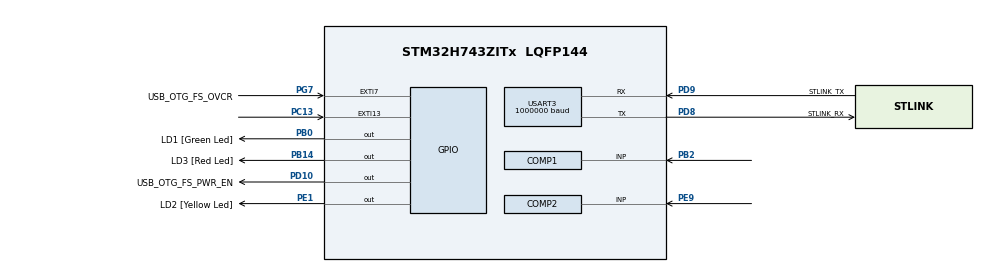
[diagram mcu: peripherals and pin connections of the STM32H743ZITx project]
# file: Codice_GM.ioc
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ADC3.Channel-0\#ChannelRegularConversion=ADC_CHANNEL_VREFINT
ADC3.ExternalTrigConv=ADC_EXTERNALTRIG_T6_TRGO
ADC3.NbrOfConversionFlag=1
ADC3.OffsetNumber-0\#ChannelRegularConversion=ADC_OFFSET_NONE
ADC3.OffsetSignedSaturation-0\#ChannelRegularConversion=DISABLE
ADC3.Rank-0\#ChannelRegularConversion=1
ADC3.SamplingTime-0\#ChannelRegularConversion=ADC_SAMPLETIME_1CYCLE_5
COMP1.Hysteresis=COMP_HYSTERESIS_MEDIUM
COMP1.TriggerMode=COMP_TRIGGERMODE_EVENT_RISING
DAC1.DAC_Channel-DAC_OUT1_Int=DAC_CHANNEL_1
Dma.ADC3.1.Direction=DMA_PERIPH_TO_MEMORY
Dma.ADC3.1.EventEnable=DISABLE
Dma.ADC3.1.FIFOMode=DMA_FIFOMODE_DISABLE
Dma.ADC3.1.Instance=DMA2_Stream0
Dma.ADC3.1.MemDataAlignment=DMA_MDATAALIGN_HALFWORD
Dma.ADC3.1.MemInc=DMA_MINC_ENABLE
Dma.ADC3.1.Mode=DMA_CIRCULAR
Dma.ADC3.1.PeriphDataAlignment=DMA_PDATAALIGN_HALFWORD
Dma.ADC3.1.PeriphInc=DMA_PINC_DISABLE
Dma.ADC3.1.Polarity=HAL_DMAMUX_REQ_GEN_RISING
Dma.ADC3.1.Priority=DMA_PRIORITY_LOW
Dma.ADC3.1.RequestNumber=1
Dma.ADC3.1.SignalID=NONE
Dma.ADC3.1.SyncEnable=DISABLE
Dma.ADC3.1.SyncPolarity=HAL_DMAMUX_SYNC_NO_EVENT
Dma.ADC3.1.SyncRequestNumber=1
Dma.ADC3.1.SyncSignalID=NONE
Dma.Request0=USART3_TX
Dma.Request1=ADC3
Dma.USART3_TX.0.Direction=DMA_MEMORY_TO_PERIPH
Dma.USART3_TX.0.EventEnable=DISABLE
Dma.USART3_TX.0.FIFOMode=DMA_FIFOMODE_DISABLE
Dma.USART3_TX.0.Instance=DMA1_Stream3
Dma.USART3_TX.0.MemDataAlignment=DMA_MDATAALIGN_BYTE
Dma.USART3_TX.0.MemInc=DMA_MINC_ENABLE
Dma.USART3_TX.0.Mode=DMA_NORMAL
Dma.USART3_TX.0.PeriphDataAlignment=DMA_PDATAALIGN_BYTE
Dma.USART3_TX.0.PeriphInc=DMA_PINC_DISABLE
Dma.USART3_TX.0.Polarity=HAL_DMAMUX_REQ_GEN_RISING
Dma.USART3_TX.0.Priority=DMA_PRIORITY_LOW
Dma.USART3_TX.0.RequestNumber=1
Dma.USART3_TX.0.SignalID=NONE
Dma.USART3_TX.0.SyncEnable=DISABLE
Dma.USART3_TX.0.SyncPolarity=HAL_DMAMUX_SYNC_NO_EVENT
Dma.USART3_TX.0.SyncRequestNumber=1
Dma.USART3_TX.0.SyncSignalID=NONE
Mcu.Family=STM32H7
Mcu.Name=STM32H743ZITx
Mcu.Package=LQFP144
NVIC.ADC3_IRQn=true\:0\:0\:false\:false\:true\:true\:true\:true
NVIC.DMA1_Stream3_IRQn=true\:0\:0\:false\:false\:true\:false\:true\:true
NVIC.DMA2_Stream0_IRQn=true\:0\:0\:false\:false\:true\:false\:true\:true
NVIC.EXTI15_10_IRQn=true\:0\:0\:false\:false\:true\:true\:true\:true
NVIC.PriorityGroup=NVIC_PRIORITYGROUP_4
NVIC.TIM6_DAC_IRQn=true\:0\:0\:false\:false\:true\:true\:true\:true
NVIC.USART3_IRQn=true\:0\:0\:false\:false\:true\:true\:true\:true
PA1.Signal=ETH_REF_CLK
PA11.Signal=USB_OTG_FS_DM
PA12.Signal=USB_OTG_FS_DP
PA2.Signal=ETH_MDIO
PA7.Signal=ETH_CRS_DV
PA8.Signal=USB_OTG_FS_SOF
PA9.Signal=USB_OTG_FS_VBUS
PB0.GPIO_Label=LD1 [Green Led]
PB0.Signal=GPIO_Output
PB13.Signal=ETH_TXD1
PB14.GPIO_Label=LD3 [Red Led]
PB14.Signal=GPIO_Output
PB2.Mode=INP
PB2.Signal=COMP1_INP
PC1.Signal=ETH_MDC
PC13.Signal=GPXTI13
PC14-OSC32_IN\ (OSC32_IN).Mode=LSE-External-Oscillator
PC14-OSC32_IN\ (OSC32_IN).Signal=RCC_OSC32_IN
PC15-OSC32_OUT\ (OSC32_OUT).Mode=LSE-External-Oscillator
PC15-OSC32_OUT\ (OSC32_OUT).Signal=RCC_OSC32_OUT
PC4.Signal=ETH_RXD0
PC5.Signal=ETH_RXD1
PD10.GPIO_Label=USB_OTG_FS_PWR_EN
PD10.Signal=GPIO_Output
PD8.GPIO_Label=STLINK_RX
PD8.Mode=Asynchronous
PD8.Signal=USART3_TX
PD9.GPIO_Label=STLINK_TX
PD9.Mode=Asynchronous
PD9.Signal=USART3_RX
PE1.GPIO_Label=LD2 [Yellow Led]
PE1.Signal=GPIO_Output
PE9.Mode=INP
PE9.Signal=COMP2_INP
PG11.Signal=ETH_TX_EN
PG13.Signal=ETH_TXD0
PG7.GPIO_Label=USB_OTG_FS_OVCR
PG7.Signal=GPXTI7
PH0-OSC_IN\ (PH0).Mode=HSE-External-Clock-Source
PH0-OSC_IN\ (PH0).Signal=RCC_OSC_IN
PH1-OSC_OUT\ (PH1).Signal=RCC_OSC_OUT
ProjectManager.HeapSize=0x200
ProjectManager.StackSize=0x400
ProjectManager.TargetToolchain=STM32CubeIDE
RCC.ADCFreq_Value=80000000
RCC.APB1Freq_Value=120000000
RCC.APB2Freq_Value=120000000
RCC.APB3Freq_Value=120000000
RCC.APB4Freq_Value=120000000
RCC.CortexFreq_Value=480000000
RCC.D1PPRE=RCC_APB3_DIV2
RCC.D2PPRE1=RCC_APB1_DIV2
RCC.D2PPRE2=RCC_APB2_DIV2
RCC.D3PPRE=RCC_APB4_DIV2
RCC.DIVM1=4
RCC.DIVM2=4
RCC.DIVN1=60
RCC.DIVN2=10
RCC.DIVQ1=4
RCC.HCLKFreq_Value=240000000
RCC.HPRE=RCC_HCLK_DIV2
RCC.HSE_VALUE=8000000
RCC.PLL2FRACN=0
RCC.PLL3FRACN=0
RCC.PLLFRACN=0
RCC.PWR_Regulator_Voltage_Scale=PWR_REGULATOR_VOLTAGE_SCALE0
RCC.SYSCLKFreq_VALUE=480000000
RCC.SYSCLKSource=RCC_SYSCLKSOURCE_PLLCLK
RCC.USBFreq_Value=240000000
TIM6.TIM_MasterOutputTrigger=TIM_TRGO_UPDATE
USART3.BaudRate=1000000
USART3.VirtualMode-Asynchronous=VM_ASYNC
VP_ADC3_TempSens_Input.Mode=IN-TempSens
VP_ADC3_Vref_Input.Mode=IN-Vrefint
VP_COMP1_VS_DACOUT1.Mode=INM_DACOUT1
VP_COMP2_VS_DACOUT1.Mode=INM_DACOUT1
VP_DAC1_VS_DACI1.Mode=DAC_OUT1_Int
VP_MEMORYMAP_VS_MEMORYMAP.Mode=CurAppReg
VP_TIM6_VS_ClockSourceINT.Mode=Enable_Timer
VP_VREFBUF_V_VREFBUF.Mode=ExternalMode
board=NUCLEO-H743ZI2

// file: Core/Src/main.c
/* USER CODE BEGIN Header */
/**
  ******************************************************************************
  * @file           : main.c
  * @brief          : Main program body
  ******************************************************************************
  * @attention
  *
  * Copyright (c) 2024 STMicroelectronics.
  * All rights reserved.
  *
  * This software is licensed under terms that can be found in the LICENSE file
  * in the root directory of this software component.
  * If no LICENSE file comes with this software, it is provided AS-IS.
  *
  ******************************************************************************
  */
/* USER CODE END Header */
#include "main.h"
#include "adc.h"
#include "comp.h"
#include "dac.h"
#include "dma.h"
#include "memorymap.h"
#include "tim.h"
#include "usart.h"
#include "gpio.h"

/* USER CODE BEGIN PTD */
#include "USART_RT.h"
#include "exponential.h"
#include "temp_volt.h"
#include "SiPM.h"
#include "LED.h"

/* USER CODE END PTD */

void SystemClock_Config(void);

int main(void)
{

  /* MCU Configuration--------------------------------------------------------*/

  /* Reset of all peripherals, Initializes the Flash interface and the Systick. */
  HAL_Init();

  /* Configure the system clock */
  SystemClock_Config();

  /* Initialize all configured peripherals */
  MX_GPIO_Init();
  MX_DMA_Init();
  MX_TIM6_Init();
  MX_USART3_UART_Init();
  MX_ADC3_Init();
  MX_DAC1_Init();
  MX_COMP1_Init();
  /* USER CODE BEGIN 2 */

  //**********************//

  //Il codice è organizzato nel sefuente modo:
  //nel main.c sono presenti tutte le esperienze commentate a seconda della necessità.
  //In questo caso l'esperienza selezionata è la catena di acqusizione dei fotoni tramite SiPM.
  //in alternativa si commenti tale sezione e si scommenti quelle interessate.

  //**********************//

// SiPM
  SiPM_comp_iniz();
  SiPM_timer_iniz();
  SiPM_DMA_iniz();
  SiPM_ADC_iniz();
  SiPM_USART_iniz();

//	USART_RT
//	RT_USART_iniz();

//	esponenziali
//	exp_USART_iniz();

//  temp_volt
//  temp_volt_ADC_iniz();
//  temp_volt_USART_iniz();

//	LED
//	LED_iniz();

  /* USER CODE END 2 */

  /* Infinite loop */
  while (1){

  }
}

void SystemClock_Config(void)
{
  RCC_OscInitTypeDef RCC_OscInitStruct = {0};
  RCC_ClkInitTypeDef RCC_ClkInitStruct = {0};

  /** Supply configuration update enable
  */
  HAL_PWREx_ConfigSupply(PWR_LDO_SUPPLY);

  /** Configure the main internal regulator output voltage
  */
  __HAL_PWR_VOLTAGESCALING_CONFIG(PWR_REGULATOR_VOLTAGE_SCALE1);

  while(!__HAL_PWR_GET_FLAG(PWR_FLAG_VOSRDY)) {}

  __HAL_RCC_SYSCFG_CLK_ENABLE();
  __HAL_PWR_VOLTAGESCALING_CONFIG(PWR_REGULATOR_VOLTAGE_SCALE0);

  while(!__HAL_PWR_GET_FLAG(PWR_FLAG_VOSRDY)) {}

  /** Initializes the RCC Oscillators according to the specified parameters
  * in the RCC_OscInitTypeDef structure.
  */
  RCC_OscInitStruct.OscillatorType = RCC_OSCILLATORTYPE_HSI;
  RCC_OscInitStruct.HSIState = RCC_HSI_DIV1;
  RCC_OscInitStruct.HSICalibrationValue = RCC_HSICALIBRATION_DEFAULT;
  RCC_OscInitStruct.PLL.PLLState = RCC_PLL_ON;
  RCC_OscInitStruct.PLL.PLLSource = RCC_PLLSOURCE_HSI;
  RCC_OscInitStruct.PLL.PLLM = 4;
  RCC_OscInitStruct.PLL.PLLN = 60;
  RCC_OscInitStruct.PLL.PLLP = 2;
  RCC_OscInitStruct.PLL.PLLQ = 4;
  RCC_OscInitStruct.PLL.PLLR = 2;
  RCC_OscInitStruct.PLL.PLLRGE = RCC_PLL1VCIRANGE_3;
  RCC_OscInitStruct.PLL.PLLVCOSEL = RCC_PLL1VCOWIDE;
  RCC_OscInitStruct.PLL.PLLFRACN = 0;
  if (HAL_RCC_OscConfig(&RCC_OscInitStruct) != HAL_OK)
  {
    Error_Handler();
  }

  /** Initializes the CPU, AHB and APB buses clocks
  */
  RCC_ClkInitStruct.ClockType = RCC_CLOCKTYPE_HCLK|RCC_CLOCKTYPE_SYSCLK
                              |RCC_CLOCKTYPE_PCLK1|RCC_CLOCKTYPE_PCLK2
                              |RCC_CLOCKTYPE_D3PCLK1|RCC_CLOCKTYPE_D1PCLK1;
  RCC_ClkInitStruct.SYSCLKSource = RCC_SYSCLKSOURCE_PLLCLK;
  RCC_ClkInitStruct.SYSCLKDivider = RCC_SYSCLK_DIV1;
  RCC_ClkInitStruct.AHBCLKDivider = RCC_HCLK_DIV2;
  RCC_ClkInitStruct.APB3CLKDivider = RCC_APB3_DIV2;
  RCC_ClkInitStruct.APB1CLKDivider = RCC_APB1_DIV2;
  RCC_ClkInitStruct.APB2CLKDivider = RCC_APB2_DIV2;
  RCC_ClkInitStruct.APB4CLKDivider = RCC_APB4_DIV2;

  if (HAL_RCC_ClockConfig(&RCC_ClkInitStruct, FLASH_LATENCY_4) != HAL_OK)
  {
    Error_Handler();
  }
}

void Error_Handler(void)
{
  __disable_irq();
  while (1)
  {
  }
}
